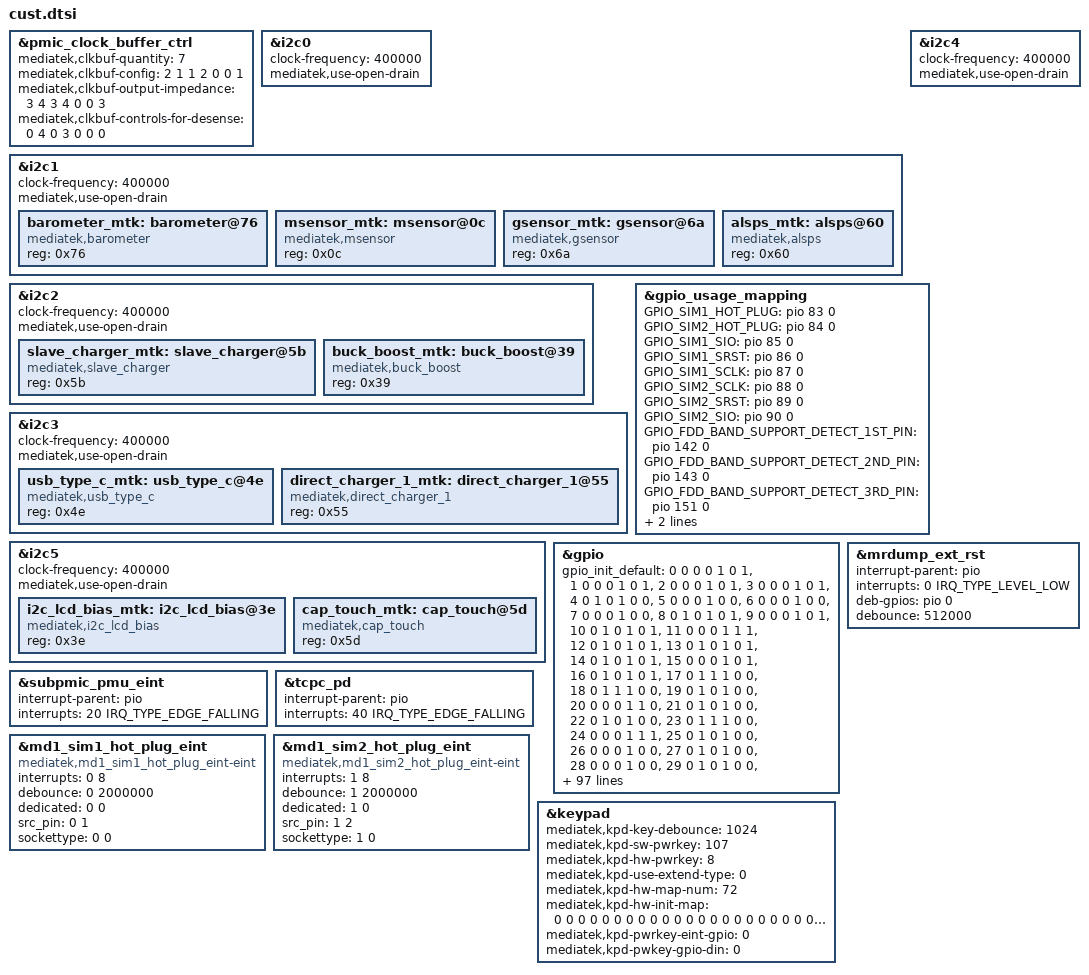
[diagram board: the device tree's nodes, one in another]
/*
 * Generated by MTK SP DrvGen Version: 3.5.160809 for MT6880.
 * 2025-06-15 08:15:03
 * Do Not Modify The File.
 * Copyright Mediatek Inc. (c) 2016.
*/

/*************************
 * ADC DTSI File
*************************/



/*************************
 * CLK_BUF DTSI File
*************************/

&pmic_clock_buffer_ctrl {
	mediatek,clkbuf-quantity = <7>;
	mediatek,clkbuf-config = <2 1 1 2 0 0 1>;
	mediatek,clkbuf-output-impedance = <3 4 3 4 0 0 3>;
	mediatek,clkbuf-controls-for-desense = <0 4 0 3 0 0 0>;
	status = "okay";
};


/*************************
 * I2C DTSI File
*************************/

&i2c0 {
	#address-cells = <1>;
	#size-cells = <0>;
	clock-frequency = <400000>;
	mediatek,use-open-drain;
};

&i2c1 {
	#address-cells = <1>;
	#size-cells = <0>;
	clock-frequency = <400000>;
	mediatek,use-open-drain;
	barometer_mtk:barometer@76 {
		compatible = "mediatek,barometer";
		reg = <0x76>;
		status = "okay";
	};

	msensor_mtk:msensor@0c {
		compatible = "mediatek,msensor";
		reg = <0x0c>;
		status = "okay";
	};

	gsensor_mtk:gsensor@6a {
		compatible = "mediatek,gsensor";
		reg = <0x6a>;
		status = "okay";
	};

	alsps_mtk:alsps@60 {
		compatible = "mediatek,alsps";
		reg = <0x60>;
		status = "okay";
	};

};

&i2c2 {
	#address-cells = <1>;
	#size-cells = <0>;
	clock-frequency = <400000>;
	mediatek,use-open-drain;
	slave_charger_mtk:slave_charger@5b {
		compatible = "mediatek,slave_charger";
		reg = <0x5b>;
		status = "okay";
	};

	buck_boost_mtk:buck_boost@39 {
		compatible = "mediatek,buck_boost";
		reg = <0x39>;
		status = "okay";
	};

};

&i2c3 {
	#address-cells = <1>;
	#size-cells = <0>;
	clock-frequency = <400000>;
	mediatek,use-open-drain;
	usb_type_c_mtk:usb_type_c@4e {
		compatible = "mediatek,usb_type_c";
		reg = <0x4e>;
		status = "okay";
	};

	direct_charger_1_mtk:direct_charger_1@55 {
		compatible = "mediatek,direct_charger_1";
		reg = <0x55>;
		status = "okay";
	};

};

&i2c4 {
	#address-cells = <1>;
	#size-cells = <0>;
	clock-frequency = <400000>;
	mediatek,use-open-drain;
};

&i2c5 {
	#address-cells = <1>;
	#size-cells = <0>;
	clock-frequency = <400000>;
	mediatek,use-open-drain;
	i2c_lcd_bias_mtk:i2c_lcd_bias@3e {
		compatible = "mediatek,i2c_lcd_bias";
		reg = <0x3e>;
		status = "okay";
	};

	cap_touch_mtk:cap_touch@5d {
		compatible = "mediatek,cap_touch";
		reg = <0x5d>;
		status = "okay";
	};

};



/*************************
 * GPIO DTSI File
*************************/

&gpio_usage_mapping {
	GPIO_SIM1_HOT_PLUG = <&pio 83 0>;
	GPIO_SIM2_HOT_PLUG = <&pio 84 0>;
	GPIO_SIM1_SIO = <&pio 85 0>;
	GPIO_SIM1_SRST = <&pio 86 0>;
	GPIO_SIM1_SCLK = <&pio 87 0>;
	GPIO_SIM2_SCLK = <&pio 88 0>;
	GPIO_SIM2_SRST = <&pio 89 0>;
	GPIO_SIM2_SIO = <&pio 90 0>;
	GPIO_FDD_BAND_SUPPORT_DETECT_1ST_PIN = <&pio 142 0>;
	GPIO_FDD_BAND_SUPPORT_DETECT_2ND_PIN = <&pio 143 0>;
	GPIO_FDD_BAND_SUPPORT_DETECT_3RD_PIN = <&pio 151 0>;
	GPIO_FDD_BAND_SUPPORT_DETECT_4TH_PIN = <&pio 163 0>;
};

&gpio{
	gpio_init_default = <0 0 0 0 1 0 1>,
		<1 0 0 0 1 0 1>,
		<2 0 0 0 1 0 1>,
		<3 0 0 0 1 0 1>,
		<4 0 1 0 1 0 0>,
		<5 0 0 0 1 0 0>,
		<6 0 0 0 1 0 0>,
		<7 0 0 0 1 0 0>,
		<8 0 1 0 1 0 1>,
		<9 0 0 0 1 0 1>,
		<10 0 1 0 1 0 1>,
		<11 0 0 0 1 1 1>,
		<12 0 1 0 1 0 1>,
		<13 0 1 0 1 0 1>,
		<14 0 1 0 1 0 1>,
		<15 0 0 0 1 0 1>,
		<16 0 1 0 1 0 1>,
		<17 0 1 1 1 0 0>,
		<18 0 1 1 1 0 0>,
		<19 0 1 0 1 0 0>,
		<20 0 0 0 1 1 0>,
		<21 0 1 0 1 0 0>,
		<22 0 1 0 1 0 0>,
		<23 0 1 1 1 0 0>,
		<24 0 0 0 1 1 1>,
		<25 0 1 0 1 0 0>,
		<26 0 0 0 1 0 0>,
		<27 0 1 0 1 0 0>,
		<28 0 0 0 1 0 0>,
		<29 0 1 0 1 0 0>,
		<30 0 1 0 1 0 0>,
		<31 0 1 0 1 0 0>,
		<32 0 0 0 1 0 1>,
		<33 0 0 0 1 0 1>,
		<34 0 0 0 1 0 1>,
		<35 0 0 0 1 0 1>,
		<36 0 0 0 1 0 1>,
		<37 0 0 0 1 0 1>,
		<38 0 0 0 1 0 1>,
		<39 0 0 0 1 0 1>,
		<40 0 0 0 1 1 0>,
		<41 0 0 0 1 0 0>,
		<42 0 0 0 1 0 0>,
		<55 1 0 0 0 0 1>,
		<56 1 0 0 1 1 1>,
		<57 1 0 0 1 1 1>,
		<58 1 0 0 1 1 1>,
		<59 1 0 0 1 1 1>,
		<60 1 0 0 1 1 1>,
		<61 0 0 0 1 0 0>,
		<62 0 0 0 1 0 0>,
		<63 0 0 0 1 0 0>,
		<64 0 1 1 1 1 0>,
		<65 0 0 0 1 0 1>,
		<66 0 1 1 1 1 0>,
		<67 1 0 0 1 0 1>,
		<68 1 0 0 1 0 1>,
		<69 1 0 0 1 0 1>,
		<70 1 0 0 1 0 1>,
		<71 1 0 0 1 0 1>,
		<72 1 0 0 1 0 1>,
		<73 1 0 0 1 0 1>,
		<74 1 0 0 1 0 1>,
		<75 1 0 0 1 0 1>,
		<76 1 0 0 1 0 1>,
		<77 1 0 0 1 0 1>,
		<78 1 0 0 1 0 1>,
		<79 1 0 0 1 1 1>,
		<80 1 0 0 1 1 1>,
		<81 1 0 0 1 1 1>,
		<82 1 0 0 1 1 1>,
		<83 1 0 0 1 1 1>,
		<84 1 0 0 1 1 1>,
		<85 1 0 0 1 1 0>,
		<86 1 0 0 1 0 0>,
		<87 1 0 0 1 0 0>,
		<88 1 0 0 1 0 0>,
		<89 1 0 0 1 0 0>,
		<90 1 0 0 1 1 0>,
		<91 1 0 0 1 0 1>,
		<92 1 0 0 1 0 1>,
		<93 1 0 0 1 0 1>,
		<94 1 0 0 1 0 1>,
		<95 1 0 0 1 0 1>,
		<96 1 0 0 1 0 1>,
		<97 1 0 0 1 0 1>,
		<98 1 0 0 1 0 1>,
		<99 1 0 0 1 0 1>,
		<100 1 0 0 1 0 1>,
		<101 1 0 0 1 0 1>,
		<102 1 0 0 1 0 1>,
		<103 1 0 0 1 0 1>,
		<104 1 0 0 1 0 1>,
		<105 1 0 0 1 1 0>,
		<106 1 0 0 1 1 0>,
		<107 1 0 0 1 1 0>,
		<108 1 0 0 1 1 0>,
		<109 1 0 0 1 1 0>,
		<110 1 0 0 1 1 0>,
		<111 1 0 0 1 0 1>,
		<112 1 0 0 1 0 1>,
		<113 1 0 0 1 0 1>,
		<114 1 0 0 1 0 1>,
		<115 1 0 0 1 0 1>,
		<116 1 0 0 1 0 1>,
		<117 1 0 0 1 0 1>,
		<118 1 0 0 1 0 0>,
		<119 1 0 0 1 1 1>,
		<120 1 0 0 1 0 1>,
		<121 1 0 0 0 0 1>,
		<122 1 0 0 0 0 1>,
		<123 1 0 0 0 0 1>,
		<124 1 0 0 0 0 1>,
		<125 1 0 0 1 0 0>,
		<126 1 0 0 1 0 0>,
		<127 0 0 0 1 0 0>,
		<128 0 0 0 1 0 0>,
		<129 0 0 0 1 0 0>,
		<130 1 0 0 1 0 0>,
		<131 1 0 0 1 0 0>,
		<132 1 0 0 1 0 0>,
		<133 1 0 0 1 1 0>,
		<134 0 1 0 1 0 0>,
		<135 0 1 0 1 0 0>,
		<136 1 0 0 1 0 0>,
		<137 1 0 0 1 0 0>,
		<138 1 0 0 0 0 0>,
		<139 1 0 0 1 0 0>,
		<140 1 0 0 0 0 0>,
		<141 1 0 0 1 0 0>,
		<142 0 0 0 1 0 0>,
		<143 0 0 0 1 0 0>,
		<144 1 0 0 0 0 0>,
		<145 1 0 0 0 0 0>,
		<146 1 0 0 0 0 0>,
		<147 1 0 0 0 0 0>,
		<148 1 0 0 0 0 0>,
		<149 1 0 0 0 0 0>,
		<150 0 1 1 1 0 0>,
		<151 0 0 0 1 0 1>,
		<152 1 0 0 0 0 0>,
		<153 1 0 0 0 0 0>,
		<154 0 0 0 1 1 0>,
		<155 1 0 0 0 0 0>,
		<156 1 0 0 0 0 0>,
		<157 1 0 0 0 0 0>,
		<158 1 0 0 0 0 0>,
		<159 1 0 0 0 0 0>,
		<160 1 0 0 0 0 0>,
		<161 1 0 0 0 0 0>,
		<162 1 0 0 0 0 0>,
		<163 0 0 0 1 0 0>,
		<164 1 0 0 0 0 0>,
		<165 1 0 0 1 0 0>,
		<166 1 0 0 1 0 0>,
		<167 1 0 0 1 0 0>,
		<168 1 0 0 1 0 0>,
		<169 1 0 0 1 1 0>,
		<170 1 0 0 1 1 0>,
		<171 1 0 0 1 1 0>,
		<172 1 0 0 1 1 0>,
		<173 1 0 0 1 0 0>,
		<174 1 0 0 1 0 0>,
		<175 1 0 0 1 0 0>,
		<176 1 0 0 1 0 0>,
		<177 1 0 0 1 0 0>,
		<178 1 0 0 1 0 0>,
		<179 1 0 0 1 0 0>,
		<180 1 0 0 1 0 0>,
		<181 7 0 0 1 1 0>,
		<182 7 0 0 1 1 0>,
		<183 1 0 0 1 0 0>,
		<184 1 0 0 1 0 0>,
		<185 7 0 0 0 0 0>,
		<186 7 0 0 1 0 0>,
		<187 7 0 0 1 0 0>,
		<188 7 0 0 1 0 0>,
		<189 7 0 0 0 0 0>,
		<190 7 0 0 1 0 0>,
		<191 7 0 0 1 0 0>,
		<192 7 0 0 1 0 0>,
		<193 1 0 0 1 0 0>,
		<194 1 0 0 1 0 0>,
		<195 1 0 0 1 0 0>,
		<196 1 0 0 1 0 0>,
		<197 1 0 0 1 1 0>,
		<198 1 0 0 1 1 0>,
		<199 0 0 0 1 0 0>,
		<200 0 0 0 1 0 0>,
		<201 0 0 0 1 0 0>,
		<202 0 0 0 1 0 0>,
		<203 7 0 0 1 0 0>,
		<204 7 0 0 1 0 0>,
		<205 7 0 0 1 0 0>,
		<206 1 0 0 1 0 1>,
		<207 1 0 0 1 0 1>,
		<208 1 0 0 1 0 1>,
		<209 0 1 0 0 0 0>,
		<210 0 1 0 0 0 0>,
		<211 0 1 0 0 0 0>,
		<212 0 1 0 0 0 0>,
		<213 0 1 0 0 0 0>,
		<214 1 0 0 1 0 0>,
		<215 1 0 0 1 0 0>,
		<216 1 0 0 1 0 0>,
		<217 1 0 0 1 0 0>,
		<218 1 0 0 1 0 0>,
		<219 1 0 0 1 0 0>,
		<220 1 0 0 1 0 0>,
		<221 1 0 0 1 0 0>,
		<222 1 0 0 1 0 0>,
		<223 1 0 0 1 0 0>,
		<224 1 0 0 1 1 0>,
		<225 1 0 0 1 1 0>,
		<226 1 0 0 1 1 0>,
		<227 1 0 0 1 1 0>,
		<228 1 0 0 1 0 0>,
		<229 1 0 0 1 0 0>,
		<230 1 0 0 1 0 1>,
		<231 2 0 0 1 0 1>,
		<232 2 0 0 1 0 1>,
		<233 2 0 0 1 0 1>,
		<234 2 0 0 1 0 1>;
};


/*************************
 * EINT DTSI File
*************************/

#include <dt-bindings/interrupt-controller/irq.h>
#include <dt-bindings/interrupt-controller/arm-gic.h>

&mrdump_ext_rst {
	interrupt-parent = <&pio>;
	interrupts = <0 IRQ_TYPE_LEVEL_LOW>;
	deb-gpios = <&pio 0 0>;
	debounce = <512000>;
	status = "okay";
};

&subpmic_pmu_eint {
	interrupt-parent = <&pio>;
	interrupts = <20 IRQ_TYPE_EDGE_FALLING>;
	status = "okay";
};

&tcpc_pd {
	interrupt-parent = <&pio>;
	interrupts = <40 IRQ_TYPE_EDGE_FALLING>;
	status = "okay";
};



/*************************
 * MD1_EINT DTSI File
*************************/

&md1_sim1_hot_plug_eint {
	compatible = "mediatek,md1_sim1_hot_plug_eint-eint";
	interrupts = <0 8>;
	debounce = <0 2000000>;
	dedicated = <0 0>;
	src_pin = <0 1>;
	sockettype = <0 0>;
	status = "okay";
};

&md1_sim2_hot_plug_eint {
	compatible = "mediatek,md1_sim2_hot_plug_eint-eint";
	interrupts = <1 8>;
	debounce = <1 2000000>;
	dedicated = <1 0>;
	src_pin = <1 2>;
	sockettype = <1 0>;
	status = "okay";
};



/*************************
 * PMIC DTSI File
*************************/



/*************************
 * POWER DTSI File
*************************/



/*************************
 * KPD DTSI File
*************************/

&keypad {
	mediatek,kpd-key-debounce = <1024>;
	mediatek,kpd-sw-pwrkey = <107>;
	mediatek,kpd-hw-pwrkey = <8>;
	mediatek,kpd-use-extend-type = <0>;
	/*HW Keycode [0~71] -> Linux Keycode*/
	mediatek,kpd-hw-map-num = <72>;
	mediatek,kpd-hw-init-map = <0 0 0 0 0 0 0 0 0 0 0 0 0 0 0 0 0 0 0 0 0 0 0 0 0 0 0 0 0 0 0 0 0 0 0 0 0 0 0 0 0 0 0 0 0 0 0 0 0 0 0 0 0 0 0 0 0 0 0 0 0 0 0 0 0 0 0 0 0 0 0 0 >;
	mediatek,kpd-pwrkey-eint-gpio = <0>;
	mediatek,kpd-pwkey-gpio-din  = <0>;
	status = "okay";
};


